# nrf54lm20b_application register map
Vendor: Nordic Semiconductor; Series: nrf54l; File version: 1
CPU: CM33 r0p4, little endian, MPU, FPU, 3 interrupt priority bits, 270 interrupts, 4 SAU regions
Registers are 32-bit, read-write, reset 0x0 unless marked. A register's access mark holds for its fields unless they carry their own. Offsets are from the block's base; [hi:lo] are bit positions; {n}, {i} and the like mark numbered series; 'fields as' and 'values as' point back to an identical list.

## GLOBAL_USBHSCORE_NS (part 1 of 2) — USBHSCORE 0
Base 0x40020000
Same registers: GLOBAL_USBHSCORE_S 0x50020000
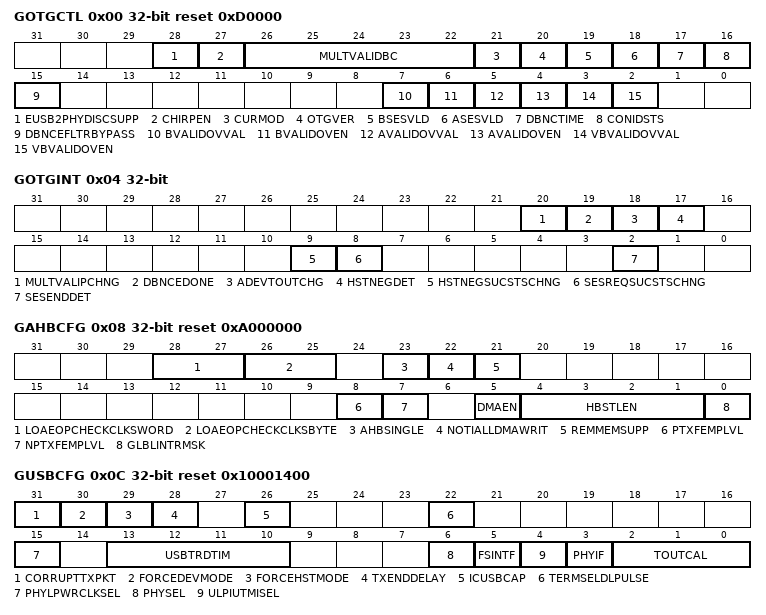
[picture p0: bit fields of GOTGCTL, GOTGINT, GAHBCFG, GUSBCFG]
0x00 GOTGCTL reset 0xD0000 — Control and Status Register
  [28] EUSB2PHYDISCSUPP — This field is only applicable to Device mode and must be set to 1'b1 if eUSB2 PHY is used.
    0=DISABLED (Device disconnect detection using GINTSTS.USBRst interrupt when not in hibernation and GPWRDN.ResetDetected when in hibernation); 1=ENABLED (Device disconnect detection using GOTGINT.SesEEndDet interrupt when not in hibernation and GPWRDN.StsChngInt when in hibernation)
  [27] CHIRPEN — Mode: Device Only. This bit when programmed to 1'b1 results in the core asserting chirp_on before sending an actual Chirp 'K' signal on USB. This bit is present only if OTG_BC_SUPPORT = 1.If OTG_BC_SUPPORT!=1, this bit is a reserved bit. Do not set this bit when core is operating in HSIC mode because HSIC always operates at High Speed and High speed chirp is not used
    0=CHIRPDISABLE (The controller does not assert chirp_on before sending an actual Chirp 'K' signal on USB.); 1=CHIRPENABLE (The controller asserts chirp_on before sending an actual Chirp 'K' signal on USB.)
  [26:22] MULTVALIDBC ro — Mode: Host and Device. Multi Valued ID pin (MultValIdBC)
    1=RIDC (B-Device connected to ACA. VBUS is on.); 2=RIDB (B-Device connected to ACA. VBUS is off.); 4=RIDA (A-Device connected to ACA); 8=RIDGND (A-Device not connected to ACA); 16=RIDFLOAT (B-Device not connected to ACA)
  [21] CURMOD ro — Current Mode of Operation (CurMod)
    0=DEVICEMODE (Current mode is device mode.); 1=HOSTMODE (Current mode is host mode.)
  [20] OTGVER — OTG Version (OTGVer)
    0=VER13 (Supports OTG Version 1.3); 1=VER20 (Supports OTG Version 2.0)
  [19] BSESVLD ro — Mode: Device only. B-Session Valid (BSesVld)
    0=NOTVALID (B-session is not valid.); 1=VALID (B-session is valid.)
  [18] ASESVLD ro — Mode: Host only. A-Session Valid (ASesVld)
    0=NOTVALID (A-session is not valid.); 1=VALID (A-session is valid.)
  [17] DBNCTIME ro — Mode: Host only. Long/Short Debounce Time (DbncTime)
    0=LONG (Long debounce time, used for physical connections (100 ms + 2.5 micro-sec)); 1=SHORT (Short debounce time, used for soft connections (2.5 micro-sec))
  [16] CONIDSTS ro — Mode: Host and Device. Connector ID Status (ConIDSts)
    0=MODEA (The core is in A-Device mode.); 1=MODEB (The core is in B-Device mode.)
  [15] DBNCEFLTRBYPASS — Mode: Host and Device. Debounce Filter Bypass
    0=DISABLED (Debounce Filter Bypass is disabled.); 1=ENABLED (Debounce Filter Bypass is enabled.)
  [7] BVALIDOVVAL — Mode: Device only. B-Peripheral Session Valid OverrideValue (BvalidOvVal)
    0=Bvalid value when GOTGCTL.BvalidOvEn =1; 1=Bvalid value when GOTGCTL.BvalidOvEn =1
  [6] BVALIDOVEN — Mode: Device only. B-Peripheral Session Valid Override Value (BvalidOvEn)
    0=DISABLED (Override is disabled and bvalid signal from the respective PHY selected is used internally by the core); 1=ENABLED (Internally Bvalid received from the PHY is overridden with GOTGCTL.BvalidOvVal)
  [5] AVALIDOVVAL — Mode: Host only. A-Peripheral Session Valid OverrideValue (AvalidOvVal)
    0=Avalid value is 1'b0 when GOTGCTL.AvalidOvEn =1; 1=Avalid value is 1'b1 when GOTGCTL.AvalidOvEn =1
  [4] AVALIDOVEN — Mode: Host only. A-Peripheral Session Valid Override Enable (AvalidOvEn)
    0=DISABLED (Derive AValid from PHY); 1=ENABLED (Derive Avalid from GOTGCTL.AvalidOvVal)
  [3] VBVALIDOVVAL — Mode: Host only. VBUS Valid OverrideValue (VbvalidOvVal)
    0=SET0 (vbusvalid value when GOTGCTL.VbvalidOvEn = 1); 1=SET1 (vbusvalid value when GOTGCTL.VbvalidOvEn is 1)
  [2] VBVALIDOVEN — Mode: Host only. VBUS Valid Override Enable (VbvalidOvEn)
    0=DISABLED (Override is disabled and bvalid signal from the respective PHY selected is used internally by the controller); 1=ENABLED (The vbus-valid signal received from the PHY is overridden with GOTGCTL.VbvalidOvVal)
0x04 GOTGINT — Interrupt Register
  [20] MULTVALIPCHNG — This bit when set indicates that there is a change in the value of at least one ACA pin value.
    0=NOACAPINCHANGE (Indicates there is no change in ACA pin value); 1=ACAPINCHANGE (Indicates there is a change in ACA pin value)
  [19] DBNCEDONE — Mode: Host only. Debounce Done (DbnceDone)
    0=INACTIVE (After Connect waiting for Debounce to complete); 1=ACTIVE (Debounce completed)
  [18] ADEVTOUTCHG — Mode: Host and Device. A-Device Timeout Change (ADevTOUTChg)
    0=INACTIVE (No A-Device Timeout); 1=ACTIVE (A-Device Timeout)
  [17] HSTNEGDET — Mode:Host and Device. Host Negotiation Detected (HstNegDet)
    0=INACTIVE (No Active HNP Request); 1=ACTIVE (Active HNP request detected)
  [9] HSTNEGSUCSTSCHNG — Mode: Host and Device. Host Negotiation Success Status Change (HstNegSucStsChng)
    0=INACTIVE (No Change); 1=ACTIVE (Host Negotiation Status Change)
  [8] SESREQSUCSTSCHNG — Mode: Host and Device. Session Request Success Status Change (SesReqSucStsChng)
    0=INACTIVE (No Change in Session Request Status); 1=ACTIVE (Session Request Status has changed)
  [2] SESENDDET — Mode: Host and Device. Session End Detected (SesEndDet)
    0=INACTIVE (Session is Active); 1=ACTIVE (SessionEnd utmiotg_bvalid signal is deasserted)
0x08 GAHBCFG reset 0xA000000 — AHB Configuration Register
  [28:27] LOAEOPCHECKCLKSWORD — Mode: Host. Number of clock cycles to check for EOP SE0 for LOA logic
    1=ONE (Check for 2 clocks of EOP SE0); 2=TWO (Check for 3 clocks of EOP SE0)
  [26:25] LOAEOPCHECKCLKSBYTE — Mode: Host. Number of clock cycles to check for EOP SE0 for LOA logic
    values as LOAEOPCHECKCLKSWORD
  [23] AHBSINGLE — Mode: Host and Device. AHB Single Support (AHBSingle)
    0=INCRBURST (The remaining data in the transfer is sent using INCR burst size); 1=SINGLEBURST (The remaining data in the transfer is sent using Single burst size)
  [22] NOTIALLDMAWRIT — Mode: Host and Device. Notify All DMA Write Transactions (NotiAllDmaWrit)
    0=LASTTRANS (Unspecified); 1=ALLTRANS (The core asserts int_dma_req for all the DMA write transactions on the AHB interface along with int_dma_done, chep_last_transact and chep_number signal informations. The core waits for sys_dma_done signal for all the DMA write transactions in order to complete the transfer of a particular Channel/Endpoint)
  [21] REMMEMSUPP — Mode: Host and Device. Remote Memory Support (RemMemSupp)
    0=DISABLED (Remote Memory Support Feature disabled); 1=ENABLED (Remote Memory Support Feature enabled)
  [8] PTXFEMPLVL — Mode: Host only. Periodic TxFIFO Empty Level (PTxFEmpLvl)
    0=HALFEMPTY (GINTSTS.PTxFEmp interrupt indicates that the Periodic TxFIFO is half empty.); 1=EMPTY (GINTSTS.PTxFEmp interrupt indicates that the Periodic TxFIFO is completely empty.)
  [7] NPTXFEMPLVL — Mode: Host and device. Non-Periodic TxFIFO Empty Level (NPTxFEmpLvl)
    0=HALFEMPTY (DIEPINTn.TxFEmp interrupt indicates that the Non-Periodic TxFIFO is half empty or that the IN Endpoint TxFIFO is half empty.); 1=EMPTY (GINTSTS.NPTxFEmp interrupt indicates that the Non-Periodic TxFIFO is completely empty or that the IN Endpoint TxFIFO is completely empty.)
  [5] DMAEN — Mode: Host and device. DMA Enable (DMAEn)
    0=COMPLETERMODE (Core operates in Completer mode); 1=DMAMODE (Core operates in a DMA mode)
  [4:1] HBSTLEN — Mode: Host and device. Burst Length/Type (HBstLen)
    0=WORD1ORSINGLE (1 word or single); 1=WORD4ORINCR (4 words or INCR); 2=WORD8 (8 words); 3=WORD16ORINCR4 (16 words or INCR4); 4=WORD32 (32 words); 5=WORD64ORINCR8 (64 words or INCR8); 6=WORD128 (128 words); 7=WORD256ORINCR16 (256 words or INCR16); 8=WORDX (Others reserved)
  [0] GLBLINTRMSK — Mode: Host and device. Global Interrupt Mask (GlblIntrMsk)
    0=MASK (Mask the interrupt assertion to the application); 1=NOMASK (Unmask the interrupt assertion to the application.)
0x0C GUSBCFG reset 0x10001400 — USB Configuration Register
  [31] CORRUPTTXPKT wo — Mode: Host and device. Corrupt Tx packet (CorruptTxPkt)
    0=Disabled (Normal Mode); 1=Enabled (Debug Mode)
  [30] FORCEDEVMODE — Mode:Host and device. Force Device Mode (ForceDevMode)
    0=DISABLED (Normal Mode); 1=ENABLED (Force Device Mode)
  [29] FORCEHSTMODE — Mode: Host and device. Force Host Mode (ForceHstMode)
    0=DISABLED (Normal Mode); 1=ENABLED (Force Host Mode)
  [28] TXENDDELAY — Mode: Device only. Tx End Delay (TxEndDelay)
    0=DISABLED (Normal Mode); 1=ENABLED (Tx End delay)
  [26] ICUSBCAP ro — Mode: Host and Device. IC_USB-Capable (IC_USBCap)
    0=NOTSELECTED (IC_USB PHY Interface is not selected); 1=SELECTED (IC_USB PHY Interface is selected)
  [22] TERMSELDLPULSE — Mode: Device only. TermSel DLine Pulsing Selection (TermSelDLPulse)
    0=TXVALID (Data line pulsing using utmi_txvalid); 1=TERMSEL (Data line pulsing using utmi_termsel)
  [15] PHYLPWRCLKSEL — PHY Low-Power Clock Select (PhyLPwrClkSel)
    0=INTPLLCLK (480-MHz Internal PLL clock); 1=EXTCLK (48-MHz External Clock)
  [13:10] USBTRDTIM — Mode: Device only. USB Turnaround Time (USBTrdTim)
    5=TURNTIME16BIT (MAC interface is 16-bit UTMI+.); 9=TURNTIME8BIT (MAC interface is 8-bit UTMI+.)
  [6] PHYSEL ro
    0=USB20 (USB 2.0 high-speed UTMI+ or ULPI PHY is selected); 1=USB11 (USB 1.1 full-speed serial transceiver is selected)
  [5] FSINTF ro — Mode: Host and Device. Full-Speed Serial Interface Select (FSIntf)
    0=FS6PIN (6-pin unidirectional full-speed serial interface); 1=FS3PIN (3-pin bidirectional full-speed serial interface)
  [4] ULPIUTMISEL ro — Mode: Host and Device. ULPI or UTMI+ Select (ULPI_UTMI_Sel)
    0=UTMI (UTMI+ Interface); 1=ULPI (ULPI Interface)
  [3] PHYIF — Mode: Host and Device. PHY Interface (PHYIf)
    0=BITS8 (PHY 8bit Mode); 1=BITS16 (PHY 16bit Mode)
  [2:0] TOUTCAL — Mode: Host and Device. HS/FS Timeout Calibration (TOutCal)
    0=ZERO (Add 0 PHY clocks); 1=ONE (Add 1 PHY clocks); 2=TWO (Add 2 PHY clocks); 3=THREE (Add 3 PHY clocks); 4=FOUR (Add 4 PHY clocks); 5=FIVE (Add 5 PHY clocks); 6=SIX (Add 6 PHY clocks); 7=SEVEN (Add 7 PHY clocks)
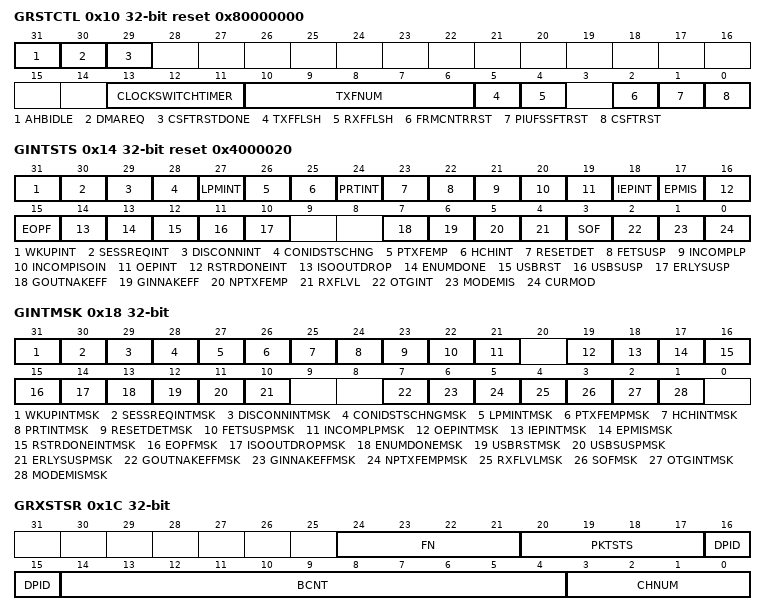
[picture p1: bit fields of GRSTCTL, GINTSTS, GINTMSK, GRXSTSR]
0x10 GRSTCTL reset 0x80000000 — Reset Register
  [31] AHBIDLE ro — Mode: Host and Device. AHB Requester Idle (AHBIdle)
    0=INACTIVE (Not Idle); 1=ACTIVE (AHB Requester Idle)
  [30] DMAREQ ro — Mode: Host and Device. DMA Request Signal (DMAReq)
    0=INACTIVE (No DMA request); 1=ACTIVE (DMA request is in progress)
  [29] CSFTRSTDONE — Mode: Host and Device. Core Soft Reset Done (CSftRstDone)
    0=INACTIVE (No reset); 1=ACTIVE (Core Soft Reset is done)
  [13:11] CLOCKSWITCHTIMER — This field is applicable if the controller is configured with multiple PHY interfaces.
    0=TIMERVALUE19 (timer value set to 19); 1=TIMERVALUE15 (timer value set to 15); 2=TIMERVALUE147 (timer value set to 147); 3=TIMERVALUE50 (timer value set to 50); 4=TIMERVALUE100 (timer value set to 100); 5=TIMERVALUE125 (timer value set to 125); 6=TIMERVALUE200 (timer value set to 200); 7=TIMERDISABLED (timer is disabled)
  [10:6] TXFNUM — Mode: Host and Device. TxFIFO Number (TxFNum)
    0=TXF0 (-Periodic TxFIFO flush in host mode -Periodic TxFIFO 0 flush in device mode when in shared FIFO operation -TXFIFO 0 flush in device mode when in dedicated FIFO mode); 1=TXF1 (-Periodic TxFIFO flush in host mode -Periodic TxFIFO 1 flush in device mode when in shared FIFO operation -TXFIFO 1 flush in device mode when in dedicated FIFO mode); {v}=TXF{v} (-Periodic TxFIFO {v} flush in device mode when in shared FIFO operation -TXFIFO {v} flush in device mode when in dedicated FIFO mode) (v=2..12); 13=TXF13 (-Periodic TxFIFO 13 flush in Device mode when in shared FIFO operation -TXFIFO 13 flush in device mode when in dedicated FIFO mode); 14=TXF14 (-Periodic TxFIFO 14 flush in Device mode when in shared FIFO operation -TXFIFO 14 flush in device mode when in dedicated FIFO mode); 15=TXF15 (-Periodic TxFIFO 15 flush in Device mode when in shared FIFO operation - TXFIFO 15 flush in device mode when in dedicated FIFO mode); 16=TXF16 (Flush all the transmit FIFOs in device or host mode)
  [5] TXFFLSH — Mode: Host and Device. TxFIFO Flush (TxFFlsh)
    0=INACTIVE (No Flush); 1=ACTIVE (Selectively flushes a single or all transmit FIFOs)
  [4] RXFFLSH — Mode: Host and Device. RxFIFO Flush (RxFFlsh)
    0=INACTIVE (Does not flush the entire RxFIFO); 1=ACTIVE (Flushes the entire RxFIFO)
  [2] FRMCNTRRST — Mode: Host only. Host Frame Counter Reset (FrmCntrRst)
    0=NOTACTIVE (No reset); 1=ACTIVE (Host Frame Counter Reset)
  [1] PIUFSSFTRST — Mode: Host and Device. PIU FS Dedicated Controller Soft Reset (PIUFSSftRst)
    0=RESETINACTIVE (No Reset); 1=RESETACTIVE (PIU FS Dedicated Controller Soft Reset)
  [0] CSFTRST — Mode: Host and Device. Core Soft Reset (CSftRst)
    0=NOTACTIVE (No reset); 1=ACTIVE (Resets hclk and phy_clock domains)
0x14 GINTSTS reset 0x4000020 — Interrupt STATUS Register
  [31] WKUPINT — Mode: Host and Device. Resume/Remote Wakeup Detected Interrupt (WkUpInt)
    0=INACTIVE (Not active); 1=ACTIVE (Resume or Remote Wakeup Detected Interrupt)
  [30] SESSREQINT — Mode: Host and Device. Session Request/New Session Detected Interrupt (SessReqInt)
    0=INACTIVE (Not active); 1=ACTIVE (Session Request New Session Detected Interrupt)
  [29] DISCONNINT — Mode: Host only. Disconnect Detected Interrupt (DisconnInt)
    0=INACTIVE (Not active); 1=ACTIVE (Disconnect Detected Interrupt)
  [28] CONIDSTSCHNG — Mode: Host and Device. Connector ID Status Change (ConIDStsChng)
    0=INACTIVE (Not Active); 1=ACTIVE (Connector ID Status Change)
  [27] LPMINT — Mode: Host and Device. LPM Transaction Received Interrupt (LPM_Int).
    0=INACTIVE (Not Active); 1=ACTIVE (LPM Transaction Received Interrupt)
  [26] PTXFEMP ro — Mode: Host only. Periodic TxFIFO Empty (PTxFEmp)
    0=INACTIVE (Not active); 1=ACTIVE (Periodic TxFIFO Empty)
  [25] HCHINT ro — Mode: Host only. Host Channels Interrupt (HChInt)
    0=INACTIVE (Not active); 1=ACTIVE (Host Channels Interrupt)
  [24] PRTINT ro — Mode: Host only. Host Port Interrupt (PrtInt)
    0=INACTIVE (Not active); 1=ACTIVE (Host Port Interrupt)
  [23] RESETDET — Mode: Device only. Reset detected Interrupt (ResetDet)
    0=INACTIVE (Not active); 1=ACTIVE (Reset detected Interrupt)
  [22] FETSUSP — Mode: Device only. Data Fetch Suspended (FetSusp)
    0=INACTIVE (Not active); 1=ACTIVE (Data Fetch Suspended)
  [21] INCOMPLP — Incomplete Periodic Transfer (incomplP)
    0=INACTIVE (Not active); 1=ACTIVE (Incomplete Periodic Transfer)
  [20] INCOMPISOIN — Mode: Device only. Incomplete Isochronous IN Transfer (incompISOIN)
    0=INACTIVE (Not active); 1=ACTIVE (Incomplete Isochronous IN Transfer)
  [19] OEPINT ro — Mode: Device only. OUT Endpoints Interrupt (OEPInt)
    0=INACTIVE (Not active); 1=ACTIVE (OUT Endpoints Interrupt)
  [18] IEPINT ro — Mode: Device only. IN Endpoints Interrupt (IEPInt)
    0=INACTIVE (Not active); 1=ACTIVE (IN Endpoints Interrupt)
  [17] EPMIS — Mode: Device only. Endpoint Mismatch Interrupt (EPMis)
    0=INACTIVE (Not active); 1=ACTIVE (Endpoint Mismatch Interrupt)
  [16] RSTRDONEINT — Mode: Device only. Restore Done Interrupt (RstrDoneInt)
    0=INACTIVE (Not active); 1=ACTIVE (Restore Done Interrupt)
  [15] EOPF — Mode: Device only. End of Periodic Frame Interrupt (EOPF)
    0=INACTIVE (Not active); 1=ACTIVE (End of Periodic Frame Interrupt)
  [14] ISOOUTDROP — Mode: Device only. Isochronous OUT Packet Dropped Interrupt (ISOOutDrop)
    0=INACTIVE (Not active); 1=ACTIVE (Isochronous OUT Packet Dropped Interrupt)
  [13] ENUMDONE — Mode: Device only. Enumeration Done (EnumDone)
    0=INACTIVE (Not active); 1=ACTIVE (Enumeration Done)
  [12] USBRST — Mode: Device only. USB Reset (USBRst)
    0=INACTIVE (Not active); 1=ACTIVE (USB Reset)
  [11] USBSUSP — Mode: Device only. USB Suspend (USBSusp)
    0=INACTIVE (Not Active); 1=ACTIVE (USB Suspend)
  [10] ERLYSUSP — Mode: Device only. Early Suspend (ErlySusp)
    0=INACTIVE (No Idle state detected); 1=ACTIVE (3ms of Idle state detected)
  [7] GOUTNAKEFF ro — Mode: Device only. Global OUT NAK Effective (GOUTNakEff)
    0=INACTIVE (Not Active); 1=ACTIVE (Global OUT NAK Effective)
  [6] GINNAKEFF ro — Mode: Device only. Global IN Non-periodic NAK Effective (GINNakEff)
    0=INACTIVE (Global Non-periodic IN NAK not active); 1=ACTIVE (Set Global Non-periodic IN NAK bit)
  [5] NPTXFEMP ro — Mode: Host and Device. Non-periodic TxFIFO Empty (NPTxFEmp)
    0=INACTIVE (Non-periodic TxFIFO is not empty); 1=ACTIVE (Non-periodic TxFIFO is empty)
  [4] RXFLVL ro — Mode: Host and Device. RxFIFO Non-Empty (RxFLvl)
    0=INACTIVE (Rx Fifo is empty); 1=ACTIVE (Rx Fifo is not empty)
  [3] SOF — Mode: Host and Device. Start of (micro)Frame (Sof)
    0=INACTIVE (No Start of Frame); 1=ACTIVE (Start of Frame)
  [2] OTGINT ro — Mode: Host and Device. OTG Interrupt (OTGInt)
    0=INACTIVE (No Interrupt); 1=ACTIVE (OTG Interrupt)
  [1] MODEMIS — Mode: Host and Device. Mode Mismatch Interrupt (ModeMis)
    0=INACTIVE (No Mode Mismatch Interrupt); 1=ACTIVE (Mode Mismatch Interrupt)
  [0] CURMOD ro — Mode: Host and Device. Current Mode of Operation (CurMod)
    0=DEVICE (Device mode); 1=HOST (Host mode)
0x18 GINTMSK — Interrupt Mask Register
  [31] WKUPINTMSK — Mode: Host and Device. Resume/Remote Wakeup Detected Interrupt Mask (WkUpIntMsk)
    0=MASK (Resume or Remote Wakeup Detected Interrupt Mask); 1=NOMASK (Unmask Resume Remote Wakeup Detected Interrupt)
  [30] SESSREQINTMSK — Mode: Host and Device. Session Request/New Session Detected Interrupt Mask (SessReqIntMsk)
    0=MASK (Session Request or New Session Detected Interrupt Mask); 1=NOMASK (No Session Request or New Session Detected Interrupt Mask)
  [29] DISCONNINTMSK — Mode: Host and Device. Disconnect Detected Interrupt Mask (DisconnIntMsk)
    0=MASK (Disconnect Detected Interrupt Mask); 1=NOMASK (No Disconnect Detected Interrupt Mask)
  [28] CONIDSTSCHNGMSK — Mode: Host and Device. Connector ID Status Change Mask (ConIDStsChngMsk)
    0=MASK (Connector ID Status Change Mask); 1=NOMASK (No Connector ID Status Change Mask)
  [27] LPMINTMSK — Mode: Host and Device. LPM Transaction Received Interrupt (LPM_Int)
    0=MASK (LPM Transaction received interrupt Mask); 1=NOMASK (No LPM Transaction received interrupt Mask)
  [26] PTXFEMPMSK — Mode: Host only. Periodic TxFIFO Empty Mask (PTxFEmpMsk)
    0=MASK (Periodic TxFIFO Empty Mask); 1=NOMASK (No Periodic TxFIFO Empty Mask)
  [25] HCHINTMSK — Mode: Host only. Host Channels Interrupt Mask (HChIntMsk)
    0=MASK (Host Channels Interrupt Mask); 1=NOMASK (No Host Channels Interrupt Mask)
  [24] PRTINTMSK — Mode: Host only. Host Port Interrupt Mask (PrtIntMsk)
    0=MASK (Host Port Interrupt Mask); 1=NOMASK (No Host Port Interrupt Mask)
  [23] RESETDETMSK — Mode: Device only. Reset detected Interrupt Mask (ResetDetMsk)
    0=MASK (Reset detected Interrupt Mask); 1=NOMASK (No Reset detected Interrupt Mask)
  [22] FETSUSPMSK — Mode: Device only. Data Fetch Suspended Mask (FetSuspMsk)
    0=MASK (Data Fetch Suspended Mask); 1=NOMASK (No Data Fetch Suspended Mask)
  [21] INCOMPLPMSK — Incomplete Periodic Transfer Mask (incomplPMsk)
    0=MASK (Host mode: Incomplete Periodic Transfer MaskDevice mode: Incomplete Isochronous OUT Transfer Mask); 1=NOMASK (Host mode: No Incomplete Periodic Transfer MaskDevice mode: No Incomplete Isochronous OUT Transfer Mask)
  [19] OEPINTMSK — Mode: Device only. OUT Endpoints Interrupt Mask (OEPIntMsk)
    0=MASK (OUT Endpoints Interrupt Mask); 1=NOMASK (No OUT Endpoints Interrupt Mask)
  [18] IEPINTMSK — Mode: Device only. IN Endpoints Interrupt Mask (IEPIntMsk)
    0=MASK (IN Endpoints Interrupt Mask); 1=NOMASK (No IN Endpoints Interrupt Mask)
  [17] EPMISMSK — Mode: Device only. Endpoint Mismatch Interrupt Mask (EPMisMsk)
    0=MASK (Endpoint Mismatch Interrupt Mask); 1=NOMASK (No Endpoint Mismatch Interrupt Mask)
  [16] RSTRDONEINTMSK — Mode: Host and Device. Restore Done Interrupt Mask (RstrDoneIntMsk)
    0=MASK (Restore Done Interrupt Mask); 1=NOMASK (No Restore Done Interrupt Mask)
  [15] EOPFMSK — Mode: Device only. End of Periodic Frame Interrupt Mask (EOPFMsk)
    0=MASK (End of Periodic Frame Interrupt Mask); 1=NOMASK (No End of Periodic Frame Interrupt Mask)
  [14] ISOOUTDROPMSK — Mode: Device only. Isochronous OUT Packet Dropped Interrupt Mask (ISOOutDropMsk)
    0=MASK (Isochronous OUT Packet Dropped Interrupt Mask); 1=NOMASK (No Isochronous OUT Packet Dropped Interrupt Mask)
  [13] ENUMDONEMSK — Mode: Device only. Enumeration Done Mask (EnumDoneMsk)
    0=MASK (Enumeration Done Mask); 1=NOMASK (No Enumeration Done Mask)
  [12] USBRSTMSK — Mode: Device only. USB Reset Mask (USBRstMsk)
    0=MASK (USB Reset Mask); 1=NOMASK (No USB Reset Mask)
  [11] USBSUSPMSK — Mode: Device only. USB Suspend Mask (USBSuspMsk)
    0=MASK (USB Suspend Mask); 1=NOMASK (No USB Suspend Mask)
  [10] ERLYSUSPMSK — Mode: Device only. Early Suspend Mask (ErlySuspMsk)
    0=MASK (Early Suspend Mask); 1=NOMASK (No Early Suspend Mask)
  [7] GOUTNAKEFFMSK — Mode: Device only. Global OUT NAK Effective Mask (GOUTNakEffMsk)
    0=MASK (Global OUT NAK Effective Mask); 1=NOMASK (No Global OUT NAK Effective Mask)
  [6] GINNAKEFFMSK — Mode: Device only,. Global Non-periodic IN NAK Effective Mask (GINNakEffMsk)
    0=MASK (Global Non-periodic IN NAK Effective Mask); 1=NOMASK (No Global Non-periodic IN NAK Effective Mask)
  [5] NPTXFEMPMSK — Mode: Host and Device. Non-periodic TxFIFO Empty Mask (NPTxFEmpMsk)
    0=MASK (Non-periodic TxFIFO Empty Mask); 1=NOMASK (No Non-periodic TxFIFO Empty Mask)
  [4] RXFLVLMSK — Mode: Host and Device. Receive FIFO Non-Empty Mask (RxFLvlMsk)
    0=MASK (Receive FIFO Non-Empty Mask); 1=NOMASK (No Receive FIFO Non-Empty Mask)
  [3] SOFMSK — Mode: Host and Device. Start of (micro)Frame Mask (SofMsk)
    0=MASK (Start of Frame Mask); 1=NOMASK (No Start of Frame Mask)
  [2] OTGINTMSK — Mode: Host and Device. OTG Interrupt Mask (OTGIntMsk)
    0=MASK (OTG Interrupt Mask); 1=NOMASK (No OTG Interrupt Mask)
  [1] MODEMISMSK — Mode: Host and Device. Mode Mismatch Interrupt Mask (ModeMisMsk)
    0=MASK (Mode Mismatch Interrupt Mask); 1=NOMASK (No Mode Mismatch Interrupt Mask)
0x1C GRXSTSR — Receive Status Debug Read Register
  [24:21] FN ro — Mode: Device only. Frame Number (FN)
  [20:17] PKTSTS ro — Packet Status (PktSts) indicates the status of the received packet.
    1=OUTNAK (Global OUT NAK in device mode (triggers an interrupt)); 2=INOUTDPRX (IN data packet received in host mode and OUT data packet received in device mode); 3=INOUTTRCOM (IN or OUT transfer completed in both host and device mode (triggers an interrupt)); 4=DSETUPCOM (SETUP transaction completed in device mode (triggers an interrupt)); 5=DTTOG (Data toggle error (triggers an interrupt) in host mode); 6=DSETUPRX (SETUP data packet received in device mode); 7=CHHALT (Channel halted in host mode (triggers an interrupt))
  [16:15] DPID ro — Data PID (DPID)
    0=DATA0; 1=DATA2; 2=DATA1; 3=MDATA
  [14:4] BCNT ro — Byte Count (BCnt)
  [3:0] CHNUM ro — Channel Number (ChNum)
    {v}=CHEP{v} (Channel or EndPoint {v}) (v=0..15)
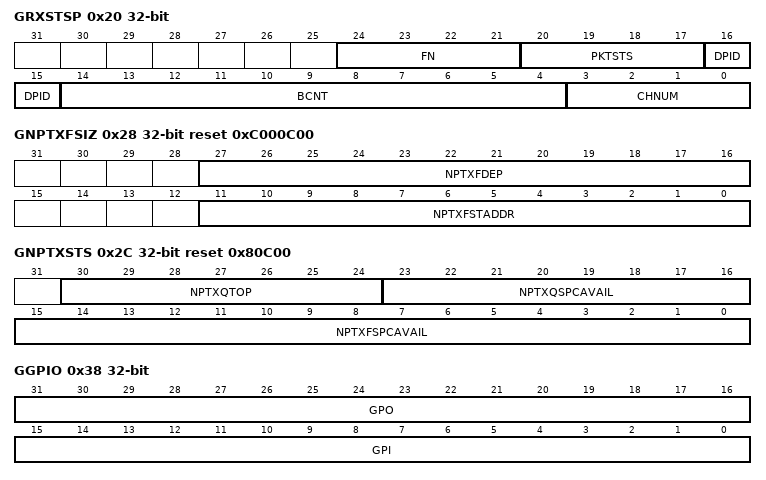
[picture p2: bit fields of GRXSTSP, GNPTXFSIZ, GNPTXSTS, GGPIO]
0x20 GRXSTSP — Receive Status Read/Pop Register
  [24:21] FN ro — Mode: Device only. Frame Number (FN)
  [20:17] PKTSTS ro — Packet Status (PktSts) indicates the status of the received packet.
    1=OUTNAK (Global OUT NAK in device mode (triggers an interrupt)); 2=INOUTDPRX (IN data packet received in host mode and OUT data packet received in device mode); 3=INOUTTRCOM (IN or OUT transfer completed in both host and device mode (triggers an interrupt)); 4=DSETUPCOM (SETUP transaction completed in device mode (triggers an interrupt)); 5=DTTOG (Data toggle error (triggers an interrupt) in host mode)
  [16:15] DPID ro — Data PID (DPID)
    0=DATA0; 1=DATA2; 2=DATA1; 3=MDATA
  [14:4] BCNT ro — Byte Count (BCnt)
  [3:0] CHNUM ro — Channel Number (ChNum)
    {v}=CHEP{v} (Channel or EndPoint {v}) (v=0..15)
0x24 GRXFSIZ reset 0xC00 — Receive FIFO Size Register
  [11:0] RXFDEP — Mode: Host and Device. RxFIFO Depth (RxFDep)
0x28 GNPTXFSIZ reset 0xC000C00 — Non-periodic Transmit FIFO Size Register
  [27:16] NPTXFDEP — Mode: Host only. Non-periodic TxFIFO Depth (NPTxFDep)
  [11:0] NPTXFSTADDR — Non-periodic Transmit RAM Start Address (NPTxFStAddr)
0x2C GNPTXSTS reset 0x80C00 — Non-periodic Transmit FIFO/Queue Status Register
  [30:24] NPTXQTOP ro — Top of the Non-periodic Transmit Request Queue (NPTxQTop)
    0=INOUTTK (IN/OUT token); 1=ZEROTX (Zero-length transmit packet (device IN/host OUT)); 2=PINGCSPLIT (PING/CSPLIT token); 3=CHNHALT (Channel halt command)
  [23:16] NPTXQSPCAVAIL ro — Non-periodic Transmit Request Queue Space Available (NPTxQSpcAvail)
    0=FULL (Non-periodic Transmit Request Queue is full); 1=QUE1 (1 location available); {v}=QUE{v} ({v} locations available) (v=2..8)
  [15:0] NPTXFSPCAVAIL ro — Non-periodic TxFIFO Space Avail (NPTxFSpcAvail)
0x38 GGPIO — General Purpose Input/Output Register
  [31:16] GPO, [15:0] GPI ro
0x3C GUID — User ID Register
  [31:0] GUID — User ID (UserID) Application-programmable ID field.
0x40 GSNPSID reset 0x4F54500B — Synopsys ID Register
  [31:0] SYNOPSYSID ro — Release number of the controller being used currently.
0x44 GHWCFG1 — User Hardware Configuration 1 Register
  [31:0] EPDIR ro — This 32-bit field uses two bits per
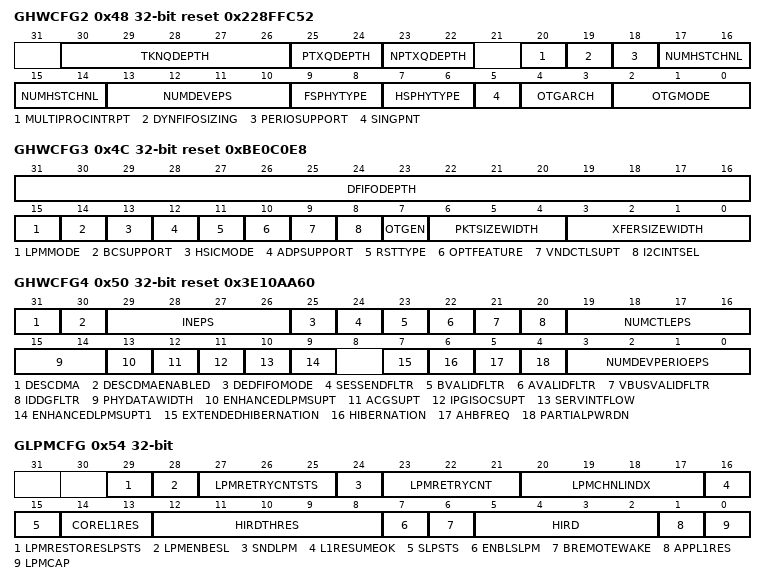
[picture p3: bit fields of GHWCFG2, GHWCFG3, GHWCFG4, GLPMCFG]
0x48 GHWCFG2 reset 0x228FFC52 — User Hardware Configuration 2 Register
  [30:26] TKNQDEPTH ro — Device Mode IN Token Sequence Learning Queue Depth (TknQDepth)
  [25:24] PTXQDEPTH ro — Host Mode Periodic Request Queue Depth (PTxQDepth)
    0=QUE2 (Queue Depth 2); 1=QUE4 (Queue Depth 4); 2=QUE8 (Queue Depth 8); 3=QUE16 (Queue Depth 16)
  [23:22] NPTXQDEPTH ro — Non-periodic Request Queue Depth (NPTxQDepth)
    0=TWO (Queue size 2); 1=FOUR (Queue size 4); 2=EIGHT (Queue size 8)
  [20] MULTIPROCINTRPT ro — Multi Processor Interrupt Enabled (MultiProcIntrpt)
    0=DISABLED (No Multi Processor Interrupt Enabled); 1=ENABLED (Multi Processor Interrupt Enabled)
  [19] DYNFIFOSIZING ro — Dynamic FIFO Sizing Enabled (DynFifoSizing)
    0=DISABLED (Dynamic FIFO Sizing Disabled); 1=ENABLED (Dynamic FIFO Sizing Enabled)
  [18] PERIOSUPPORT ro — Periodic OUT Channels Supported in Host Mode (PerioSupport)
    0=DISABLED (Periodic OUT Channels is not supported in Host Mode); 1=ENABLED (Periodic OUT Channels Supported in Host Mode Supported)
  [17:14] NUMHSTCHNL ro — Number of Host Channels (NumHstChnl)
    {v}=HOSTCH{v} (Host Channel {v+1}) (v=0..15)
  [13:10] NUMDEVEPS ro — Number of Device Endpoints (NumDevEps)
    {v}=ENDPT{v} (End point {v}) (v=0..15)
  [9:8] FSPHYTYPE ro — Full-Speed PHY Interface Type (FSPhyType)
    0=NOFS (Full-speed interface not supported); 1=FS (Dedicated full-speed interface is supported); 2=FSPLUSUTMI (FS pins shared with UTMI+ pins is supported); 3=FSPLUSULPI (FS pins shared with ULPI pins is supported)
  [7:6] HSPHYTYPE ro — High-Speed PHY Interface Type (HSPhyType)
    0=NOHS (High-Speed interface not supported); 1=UTMIPLUS (High Speed Interface UTMI+ is supported); 2=ULPI (High Speed Interface ULPI is supported); 3=UTMIPUSULPI (High Speed Interfaces UTMI+ and ULPI is supported)
  [5] SINGPNT ro — Point-to-Point (SingPnt)
    0=MULTIPOINT (Multi-point application (hub and split support)); 1=SINGLEPOINT (Single-point application (no hub and split support))
  [4:3] OTGARCH ro — Architecture (OtgArch)
    0=COMPLETERMODE; 1=EXTERNALDMA (External DMA Mode); 2=INTERNALDMA (Internal DMA Mode)
  [2:0] OTGMODE ro — Mode of Operation (OtgMode)
    0=HNPSRP (HNP- and SRP-Capable OTG (Host and Device)); 1=SRPOTG (SRP-Capable OTG (Host and Device)); 2=NHNPNSRP (Non-HNP and Non-SRP Capable OTG (Host and Device)); 3=SRPCAPD (SRP-Capable Device); 4=NONOTGD (Non-OTG Device); 5=SRPCAPH (SRP-Capable Host); 6=NONOTGH (Non-OTG Host)
0x4C GHWCFG3 reset 0xBE0C0E8 — User Hardware Configuration 3 Register
  [31:16] DFIFODEPTH ro — DFIFO Depth (DfifoDepth - EP_LOC_CNT)
  [15] LPMMODE ro — LPM mode specified for Mode of Operation.
    0=DISABLED (LPM disabled); 1=ENABLED (LPM enabled)
  [14] BCSUPPORT ro — This bit indicates the controller support for Battery Charger.
    0=DISABLED (No Battery Charger Support); 1=ENABLED (Battery Charger Support present)
  [13] HSICMODE ro — HSIC mode specified for Mode of Operation
    0=DISABLED (No HSIC capability); 1=ENABLED (HSIC-capable with shared UTMI PHY interface)
  [12] ADPSUPPORT ro — This bit indicates whether ADP logic is present within or external to the controller
    0=DISABLED (ADP logic is not present along with the controller); 1=ENABLED (ADP logic is present along with the controller)
  [11] RSTTYPE ro — Reset Style for Clocked always Blocks in RTL (RstType)
    0=ASYNCRST (Asynchronous reset is used in the core); 1=SYNCRST (Synchronous reset is used in the core)
  [10] OPTFEATURE ro — Optional Features Removed (OptFeature)
    0=DISABLED (Optional features were not Removed); 1=ENABLED (Optional Features have been Removed)
  [9] VNDCTLSUPT ro — Vendor Control Interface Support (VndctlSupt)
    0=DISABLED (Vendor Control Interface is not available.); 1=ENABLED (Vendor Control Interface is available.)
  [8] I2CINTSEL ro — I2C Selection (I2CIntSel)
    0=DISABLED (I2C Interface is not available); 1=ENABLED (I2C Interface is available)
  [7] OTGEN ro — OTG Function Enabled (OtgEn)
    0=DISABLED (Not OTG Capable); 1=ENABLED (OTG Capable)
  [6:4] PKTSIZEWIDTH ro — Width of Packet Size Counters (PktSizeWidth)
    {v}=BITS{v+4} (Width of Packet Size Counter {v+4}) (v=0..6)
  [3:0] XFERSIZEWIDTH ro — Width of Transfer Size Counters (XferSizeWidth)
    {v}=WIDTH{v+11} (Width of Transfer Size Counter {v+11} bits) (v=0..8)
0x50 GHWCFG4 reset 0x3E10AA60 — User Hardware Configuration 4 Register
  [31] DESCDMA ro — Scatter/Gather DMA configuration
    0=CONFIG1 (Non Dynamic configuration); 1=CONFIG2 (Dynamic configuration)
  [30] DESCDMAENABLED ro — Scatter/Gather DMA configuration
    0=DISABLE (Non-Scatter/Gather DMA configuration); 1=ENABLE (Scatter/Gather DMA configuration)
  [29:26] INEPS ro — Number of Device Mode IN Endpoints Including Control Endpoints (INEps)
    0=ENDPT1 (1 IN Endpoint); {v}=ENDPT{v+1} ({v+1} IN Endpoints) (v=1..15)
  [25] DEDFIFOMODE ro — Enable Dedicated Transmit FIFO for device IN Endpoints
    0=DISABLED (Dedicated Transmit FIFO Operation not enabled); 1=ENABLED (Dedicated Transmit FIFO Operation enabled)
  [24] SESSENDFLTR ro — session_end Filter Enabled (SessEndFltr)
    0=DISABLED (No filter); 1=ENABLED (Filter)
  [23] BVALIDFLTR ro — b_valid Filter Enabled (BValidFltr)
    0=DISABLED (No Filter); 1=ENABLED (Filter)
  [22] AVALIDFLTR ro — a_valid Filter Enabled (AValidFltr)
    0=DISABLED (No filter); 1=ENABLED (Filter)
  [21] VBUSVALIDFLTR ro — VBUS Valid Filter Enabled (VBusValidFltr)
    0=DISABLED (Vbus Valid Filter Disabled); 1=ENABLED (Vbus Valid Filter Enabled)
  [20] IDDGFLTR ro — IDDIG Filter Enable (IddgFltr)
    0=DISABLED (Iddig Filter Disabled); 1=ENABLED (Iddig Filter Enabled)
  [19:16] NUMCTLEPS ro — Number of Device Mode Control Endpoints in Addition to
    {v}=ENDPT{v} (End point {v}) (v=0..15)
  [15:14] PHYDATAWIDTH ro — UTMI+ PHY/ULPI-to-Internal UTMI+ Wrapper Data Width
    0=WIDTH1 (8 bits); 1=WIDTH2 (16 bits); 2=WIDTH3 (8/16 bits, software selectable)
  [13] ENHANCEDLPMSUPT ro — Enhanced LPM Support (EnhancedLPMSupt)
    1=ENABLED (Enhanced LPM Support is enabled)
  [12] ACGSUPT ro — Active Clock Gating Support
    0=DISABLED (Unspecified); 1=ENABLED (Active Clock Gating Support)
  [11] IPGISOCSUPT ro — Interpacket Gap ISOC OUT Worst-case Support (ipgisocSupt)
    0=DISABLED (Interpacket Gap ISOC OUT Worst-case Support is Disabled); 1=ENABLED (Interpacket Gap ISOC OUT Worst-case Support is Enabled (Default))
  [10] SERVINTFLOW ro — Service Interval Flow
    0=DISABLED (Service Interval Flow not supported); 1=ENABLED (Service Interval Flow supported)
  [9] ENHANCEDLPMSUPT1 ro — Enhanced LPM Support1 (EnhancedLPMSupt1)
    0=DISABLED (Reject L1 Request even if Non-Periodic (Bulk/Interrupt) TxFIFO is not empty.); 1=ENABLED (Accept L1 Request even if Non-Periodic (Bulk/Interrupt) TxFIFO is not empty)
  [7] EXTENDEDHIBERNATION ro — Enable Hibernation
    0=DISABLED (Extended Hibernation feature not enabled); 1=ENABLED (Extended Hibernation feature enabled)
  [6] HIBERNATION ro — Enable Hibernation (Hibernation)
    0=DISABLED (Hibernation feature disabled); 1=ENABLED (Hibernation feature enabled)
  [5] AHBFREQ ro — Minimum AHB Frequency Less Than 60 MHz (AhbFreq)
    0=DISABLED (Minimum AHB Frequency More Than 60 MHz); 1=ENABLED (Minimum AHB Frequency Less Than 60 MHz)
  [4] PARTIALPWRDN ro — Enable Partial Power Down (PartialPwrDn)
    0=DISABLED (Partial Power Down disabled); 1=ENABLED (Partial Power Down enabled)
  [3:0] NUMDEVPERIOEPS ro — Number of Device Mode Periodic IN Endpoints (NumDevPerioEps)
    {v}=Number of Periodic IN EPs is {v} (v=0..15)
0x54 GLPMCFG — LPM Config Register
  [29] LPMRESTORESLPSTS — LPM Restore Sleep Status (LPM_RestoreSlpSts)
    0=DISABLED (Puts the core in Shallow Sleep mode based on the BESL value from the Host); 1=ENABLED (Puts the core in Deep Sleep mode based on the BESL value from the Host)
  [28] LPMENBESL — LPM Enable BESL (LPM_EnBESL)
    0=DISABLED (BESL is disabled); 1=ENABLED (BESL is enabled as defined in LPM Errata)
  [27:25] LPMRETRYCNTSTS ro — LPM Retry Count Status (LPM_RetryCnt_Sts)
    0=RETRYREM0 (Zero LPM retries remaining); 1=RETRYREM1 (One LPM retry remaining); 2=RETRYREM2 (Two LPM retries remaining); 3=RETRYREM3 (Three LPM retries remaining); 4=RETRYREM4 (Four LPM retries remaining); 5=RETRYREM5 (Five LPM retries remaining); 6=RETRYREM6 (Six LPM retries remaining); 7=RETRYREM7 (Seven LPM retries remaining)
  [24] SNDLPM — Send LPM Transaction (SndLPM)
    0=DISABLED (In host-only mode: Received the response from the device for the LPM transaction); 1=ENABLED (In host-only mode: Sending LPM transaction containing EXT and LPM tokens)
  [23:21] LPMRETRYCNT — LPM Retry Count (LPM_Retry_Cnt)
    0=RETRY0 (Zero LPM retries); 1=RETRY1 (One LPM retry); 2=RETRY2 (Two LPM retries); 3=RETRY3 (Three LPM retries); 4=RETRY4 (Four LPM retries); 5=RETRY5 (Five LPM retries); 6=RETRY6 (Six LPM retries); 7=RETRY7 (Seven LPM retries)
  [20:17] LPMCHNLINDX — LPM Channel Index
    {v}=CH{v} (Channel {v}) (v=0..14); 15=CH15 (Channel15)
  [16] L1RESUMEOK ro — Sleep State Resume OK (L1ResumeOK)
    0=NOTOK (The application/core cannot start Resume from Sleep state); 1=OK (The application/core can start Resume from Sleep state)
  [15] SLPSTS ro — Port Sleep Status (SlpSts)
    0=CORENOTINL1 (In Host or Device mode, this bit indicates core is not in L1); 1=COREINL1 (In Host mode, this bit indicates the core transitions to Sleep state as a successful LPM transaction. In Device mode, the core enters the Sleep state when an ACK response is sent to an LPM transaction)
  [14:13] COREL1RES ro — LPM Response (CoreL1Res)
    0=LPMRESP1 (ERROR : No handshake response); 1=LPMRESP2 (STALL response); 2=LPMRESP3 (NYET response); 3=LPMRESP4 (ACK response)
  [12:8] HIRDTHRES — BESL/HIRD Threshold (HIRD_Thres)
  [7] ENBLSLPM — Enable utmi_sleep_n (EnblSlpM)
    0=DISABLED (utmi_sleep_n assertion from the core is not transferred to the external PHY); 1=ENABLED (utmi_sleep_n assertion from the core is transferred to the external PHY when utmi_l1_suspend_n cannot be asserted)
  [6] BREMOTEWAKE — RemoteWakeEnable (bRemoteWake)
    0=DISABLED (Remote Wakeup is disabled); 1=ENABLED (In Host or device mode, this field takes the value of remote wake up)
  [5:2] HIRD — Host-Initiated Resume Duration (HIRD)
  [1] APPL1RES — Mode: Device only. LPM response programmed by application (AppL1Res)
    0=NYETRESP (The core responds with a NYET when an error is detected in either of the LPM token packets due to corruption); 1=ACKRESP (The core responds with an ACK only on a successful LPM transaction)
  [0] LPMCAP — LPM-Capable (LPMCap)
    0=DISABLED (LPM capability is not enabled); 1=ENABLED (LPM capability is enabled)
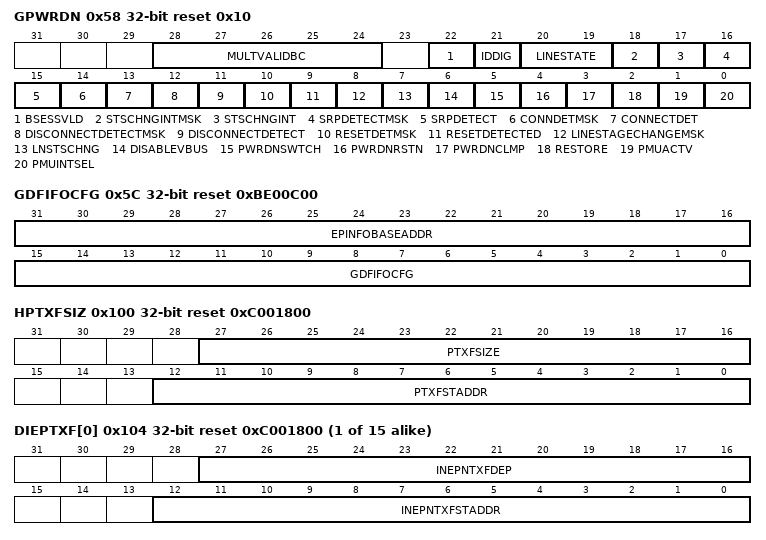
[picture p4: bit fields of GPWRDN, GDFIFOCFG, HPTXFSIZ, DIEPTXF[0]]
0x58 GPWRDN reset 0x10 — Global Power Down Register
  [28:24] MULTVALIDBC ro
    0=RID0 (OTG device as B-device); 1=RIDC (OTG device as B-device, can connect); 2=RIDB (OTG device as B-device, cannot connect); 4=RIDA (OTG device as A-device); 8=RIDGND (ID_OTG pin is grounded); 12=RIDARIDGND (OTG device as A-device, RID_A=1 and RID_GND=1); 16=RIDFLOAT (ID pull down when ID_OTG is floating); 17=RIDCRIDFLOAT (OTG device as B-device, can connect, RID_C=1 and RID_FLOAT=1); 18=RIDBRIDFLOAT (OTG device as B-device, cannot connect, RID_B=1 and RID_FLOAT=1); 31=RID1 (OTG device as A-device)
  [22] BSESSVLD ro — B Session Valid (BSessVld)
    0=NOTVALID (B_Valid is 0); 1=VALID (B_Valid is 1)
  [21] IDDIG ro — This bit indicates the status of the signal IDDIG. The application must read this bit after receiving GPWRDN.StsChngInt and decode based on the previous value stored by the application.
    0=DISABLED (Host Mode); 1=ENABLED (Device Mode)
  [20:19] LINESTATE ro
    0=LS1 (Linestate on USB: DM = 0, DP = 0); 1=LS2 (Linestate on USB: DM = 0, DP = 1); 2=LS3 (Linestate on USB: DM = 1, DP = 0); 3=LS4 (Linestate on USB: Not-defined)
  [18] STSCHNGINTMSK
    0=MASK (Mask for Status Change Interrupt); 1=NOMASK (No Status Change Interrupt Mask)
  [17] STSCHNGINT — Status Change Interrupt (StsChngInt)
    0=DISABLED (No Status change); 1=ENABLED (Status change detected)
  [16] SRPDETECTMSK
    0=NOMASK (No SRPDetect Interrupt Mask); 1=MASK (Mask for SRPDetect Interrupt)
  [15] SRPDETECT
    0=DISABLED (SRP not detected); 1=ENABLED (SRP detected)
  [14] CONNDETMSK
    0=NOMASK (No ConnectDet Interrupt Mask); 1=MASK (Mask for ConnectDet Interrupt)
  [13] CONNECTDET
    0=DISABLED (Connect not detected); 1=ENABLED (Connect detected)
  [12] DISCONNECTDETECTMSK
    0=MASK (Mask for DisconnectDetect Interrupt); 1=NOMASK (No DisconnectDetect Interrupt Mask)
  [11] DISCONNECTDETECT
    0=DISABLED (Disconnect not detected); 1=ENABLED (Disconnect detected)
  [10] RESETDETMSK
    0=MASK (Mask for ResetDetect Interrupt); 1=NOMASK (No ResetDetect Interrupt Mask)
  [9] RESETDETECTED
    0=DISABLED (Reset not detected); 1=ENABLED (Reset detected)
  [8] LINESTAGECHANGEMSK
    0=MASK (Mask for LineStateChange Interrupt); 1=NOMASK (No LineStateChange Interrupt Mask)
  [7] LNSTSCHNG — Line State Change (LnStsChng)
    0=DISABLED (No LineState change on USB); 1=ENABLED (LineState change on USB)
  [6] DISABLEVBUS
    0=DISABLED (Host mode:HPRT0.PrtPwr was not programmed to 0, and in Device mode:Session Valid); 1=ENABLED (Host mode:HPRT0.PrtPwr was programmed to 0 and in Device mode:Session End)
  [5] PWRDNSWTCH — Power Down Switch (PwrDnSwtch)
    0=ON (The controller is in ON state); 1=OFF (The controller is in OFF state)
  [4] PWRDNRSTN — Power Down ResetN (PwrDnRst_n)
    0=DISABLE (Reset the controller); 1=ENABLE (The controller is in normal operation)
  [3] PWRDNCLMP — Power Down Clamp (PwrDnClmp)
    0=DISABLE (Disable PMU power clamp); 1=ENABLE (Enable PMU power clamp)
  [2] RESTORE
    0=DISABLE (The controller in normal mode of operation); 1=ENABLE (The controller in Restore mode)
  [1] PMUACTV — PMU Active (PMUActv)
    0=DISABLE (Disable PMU module); 1=ENABLE (Enable PMU module)
  [0] PMUINTSEL — PMU Interrupt Select (PMUIntSel)
    0=DISABLE (Internal DWC_otg_core interrupt is selected); 1=ENABLE (External DWC_otg_pmu interrupt is selected)
0x5C GDFIFOCFG reset 0xBE00C00 — Global DFIFO Configuration Register
  [31:16] EPINFOBASEADDR — This field provides the start address of the EP info controller.
  [15:0] GDFIFOCFG
0x68 GINTMSK2 — Interrupt Mask Register 2
0x6C GINTSTS2 — Interrupt Register 2
0x100 HPTXFSIZ reset 0xC001800 — Host Periodic Transmit FIFO Size Register
  [27:16] PTXFSIZE — Host Periodic TxFIFO Depth (PTxFSize)
  [12:0] PTXFSTADDR — Host Periodic TxFIFO Start Address (PTxFStAddr)
{0x104+4i} DIEPTXF[{i}] (i=0..14) reset 0xC001800 — Description collection: Device IN Endpoint Transmit FIFO 1 Size Register
  [27:16] INEPNTXFDEP — IN Endpoint TxFIFO Depth (INEPnTxFDep)
  [12:0] INEPNTXFSTADDR — IN Endpoint FIFOn Transmit RAM Start Address (INEPnTxFStAddr)
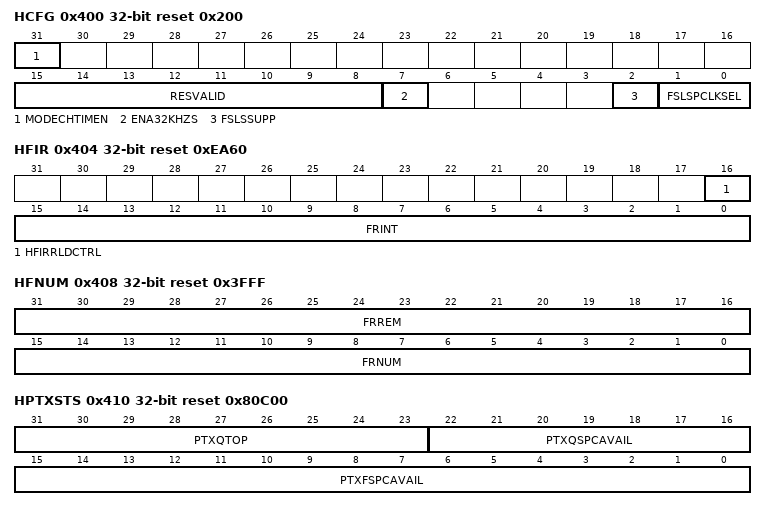
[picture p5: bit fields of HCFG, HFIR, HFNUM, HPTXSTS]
0x400 HCFG reset 0x200 — Host Configuration Register
  [31] MODECHTIMEN — Mode Change Ready Timer Enable (ModeChTimEn)
    0=ENABLED (The Host core waits for either 200 PHY clock cycles or a linestate of SE0 at the end of resume to change the opmode from 0x2 to 0x0); 1=DISABLED (The Host core waits only for a linestate of SE0 at the end of resume to change the opmode from 0x2 to 0x0)
  [15:8] RESVALID — Resume Validation Period (ResValid)
  [7] ENA32KHZS — Enable 32 KHz Suspend mode (Ena32KHzS)
    0=DISABLED (32 KHz Suspend mode disabled); 1=ENABLED (32 KHz Suspend mode enabled)
  [2] FSLSSUPP — FS- and LS-Only Support (FSLSSupp)
    0=HSFSLS (HS/FS/LS, based on the maximum speed supported by the connected device); 1=FSLS (FS/LS-only, even if the connected device can support HS)
  [1:0] FSLSPCLKSEL — FS/LS PHY Clock Select (FSLSPclkSel)
    0=CLK3060 (PHY clock is running at 30/60 MHz); 1=CLK48 (PHY clock is running at 48 MHz); 2=CLK6 (PHY clock is running at 6 MHz)
0x404 HFIR reset 0xEA60 — Host Frame Interval Register
  [16] HFIRRLDCTRL — Reload Control (HFIRRldCtrl)
    0=DISABLED (The HFIR cannot be reloaded dynamically); 1=ENABLED (The HFIR can be dynamically reloaded during runtime)
  [15:0] FRINT — Frame Interval (FrInt)
0x408 HFNUM reset 0x3FFF — Host Frame Number/Frame Time Remaining Register
  [31:16] FRREM ro — Frame Time Remaining (FrRem)
  [15:0] FRNUM ro — Frame Number (FrNum)
    0=INACTIVE (No SOF is transmitted); 1=ACTIVE (SOF is transmitted)
0x410 HPTXSTS reset 0x80C00 — Host Periodic Transmit FIFO/Queue Status Register
  [31:23] PTXQTOP ro — Top of the Periodic Transmit Request Queue (PTxQTop)
  [22:16] PTXQSPCAVAIL ro — Periodic Transmit Request Queue Space Available (PTxQSpcAvail)
    0=FULL (Periodic Transmit Request Queue is full); 1=FREE1 (1 location available); {v}=FREE{v} ({v} locations available) (v=2..15)
  [15:0] PTXFSPCAVAIL ro — Periodic Transmit Data FIFO Space Available (PTxFSpcAvail)
0x414 HAINT — Host All Channels Interrupt Register
  [15:0] HAINT ro
    0=INACTIVE (Not active); 1=ACTIVE (Host Channel Interrupt)
0x418 HAINTMSK — Host All Channels Interrupt Mask Register
  [15:0] HAINTMSK — Channel Interrupt Mask (HAINTMsk)
    0=MASK (Mask Channel interrupt); 1=UNMASK (UnMask Channel interrupt)

## Notices in the file
Copyright (c) 2010 - 2026, Nordic Semiconductor ASA All rights reserved.
SPDX-License-Identifier: BSD-3-Clause
Redistribution and use in source and binary forms, with or without
modification, are permitted provided that the following conditions are met:
1. Redistributions of source code must retain the above copyright notice, this
list of conditions and the following disclaimer.
2. Redistributions in binary form must reproduce the above copyright
notice, this list of conditions and the following disclaimer in the
documentation and/or other materials provided with the distribution.
3. Neither the name of Nordic Semiconductor ASA nor the names of its
contributors may be used to endorse or promote products derived from this
software without specific prior written permission.
THIS SOFTWARE IS PROVIDED BY THE COPYRIGHT HOLDERS AND CONTRIBUTORS "AS IS"
AND ANY EXPRESS OR IMPLIED WARRANTIES, INCLUDING, BUT NOT LIMITED TO, THE
IMPLIED WARRANTIES OF MERCHANTABILITY, AND FITNESS FOR A PARTICULAR PURPOSE
ARE DISCLAIMED. IN NO EVENT SHALL NORDIC SEMICONDUCTOR ASA OR CONTRIBUTORS BE
LIABLE FOR ANY DIRECT, INDIRECT, INCIDENTAL, SPECIAL, EXEMPLARY, OR
CONSEQUENTIAL DAMAGES (INCLUDING, BUT NOT LIMITED TO, PROCUREMENT OF
SUBSTITUTE GOODS OR SERVICES; LOSS OF USE, DATA, OR PROFITS; OR BUSINESS
INTERRUPTION) HOWEVER CAUSED AND ON ANY THEORY OF LIABILITY, WHETHER IN
CONTRACT, STRICT LIABILITY, OR TORT (INCLUDING NEGLIGENCE OR OTHERWISE)
ARISING IN ANY WAY OUT OF THE USE OF THIS SOFTWARE, EVEN IF ADVISED OF THE
POSSIBILITY OF SUCH DAMAGE.
